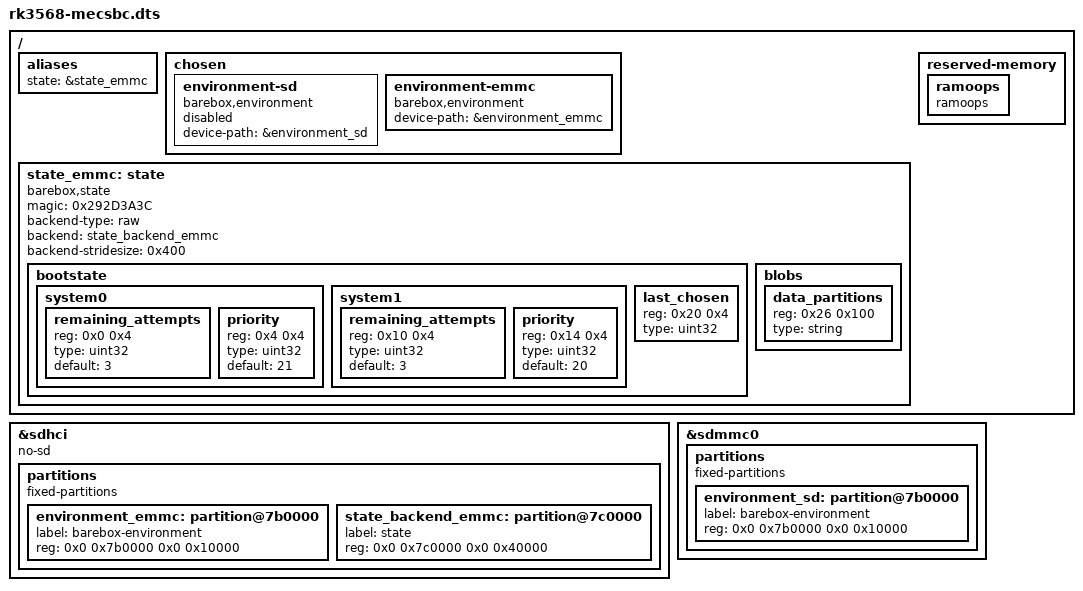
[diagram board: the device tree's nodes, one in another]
// SPDX-License-Identifier: (GPL-2.0+ OR MIT)

/dts-v1/;

#include "rk3568-mecsbc-linux.dts"
#include "rk356x.dtsi"

/ {
	aliases {
		state = &state_emmc;
	};

	chosen: chosen {
		environment-sd {
			compatible = "barebox,environment";
			device-path = &environment_sd;
			status = "disabled";
		};

		environment-emmc {
			compatible = "barebox,environment";
			device-path = &environment_emmc;
			status = "okay";
		};
	};

	state_emmc: state {
		magic = <0x292D3A3C>;
		compatible = "barebox,state";
		backend-type = "raw";
		backend = <&state_backend_emmc>;
		backend-stridesize = <0x400>;
		#address-cells = <1>;
		#size-cells = <1>;

		bootstate {
			#address-cells = <1>;
			#size-cells = <1>;

			system0 {
				#address-cells = <1>;
				#size-cells = <1>;

				remaining_attempts {
					reg = <0x0 0x4>;
					type = "uint32";
					default = <3>;
				};

				priority {
					reg = <0x4 0x4>;
					type = "uint32";
					default = <21>;
				};
			};

			system1 {
				#address-cells = <1>;
				#size-cells = <1>;

				remaining_attempts {
					reg = <0x10 0x4>;
					type = "uint32";
					default = <3>;
				};

				priority {
					reg = <0x14 0x4>;
					type = "uint32";
					default = <20>;
				};
			};

			last_chosen {
				reg = <0x20 0x4>;
				type = "uint32";
			};
		};

		blobs {
			#address-cells = <1>;
			#size-cells = <1>;

			data_partitions {
				reg = <0x26 0x100>;
				type = "string";
			};
		};
	};

	reserved-memory {
		#address-cells = <2>;
		#size-cells = <2>;
		ranges;

		/* Address will be determined by the bootloader */
		ramoops {
			compatible = "ramoops";
		};
	};
};

&sdhci {
	no-sd;

	partitions {
		compatible = "fixed-partitions";
		#address-cells = <2>;
		#size-cells = <2>;

		/* eMMC reserved 8MiB for barebox (2 copies?), env and state */
		environment_emmc: partition@7b0000 {
			label = "barebox-environment";
			reg = <0x0 0x7b0000 0x0 0x10000>;
		};

		/* eMMC state after barebox and environment */
		state_backend_emmc: partition@7c0000 {
			label = "state";
			reg = <0x0 0x7c0000 0x0 0x40000>;
		};
	};
};

&sdmmc0 {
	partitions {
		compatible = "fixed-partitions";
		#address-cells = <2>;
		#size-cells = <2>;

		environment_sd: partition@7b0000 {
			label = "barebox-environment";
			reg = <0x0 0x7b0000 0x0 0x10000>;
		};
	};
};
